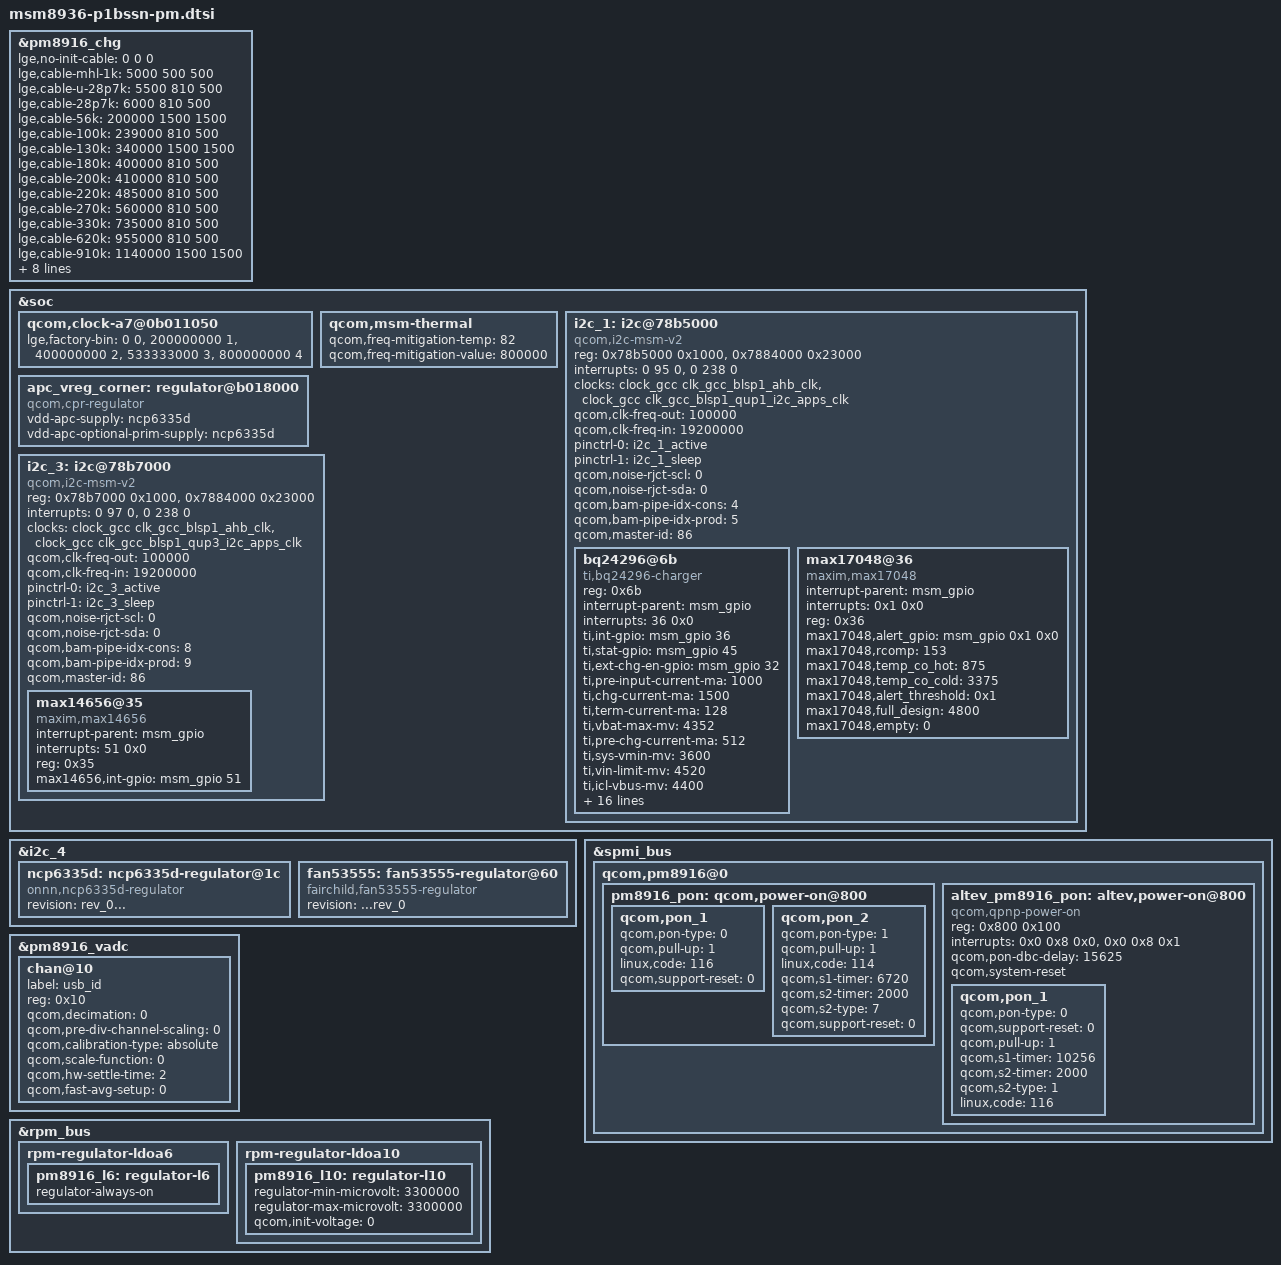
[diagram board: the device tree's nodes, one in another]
/* Copyright (c) 2012, Code Aurora Forum. All rights reserved.
 *
 * This program is free software; you can redistribute it and/or modify
* it under the terms of the GNU General Public License version 2 and
* only version 2 as published by the Free Software Foundation.
*
* This program is distributed in the hope that it will be useful,
* but WITHOUT ANY WARRANTY; without even the implied warranty of
* MERCHANTABILITY or FITNESS FOR A PARTICULAR PURPOSE.  See the
* GNU General Public License for more details.
*/

&pm8916_chg {
	status = "ok";

	lge,no-init-cable = <0 0 0>;
	lge,cable-mhl-1k = <5000 500 500>;
	lge,cable-u-28p7k = <5500 810 500>;
	lge,cable-28p7k = <6000 810 500>;
	lge,cable-56k = <200000 1500 1500>;
	lge,cable-100k = <239000 810 500>;
	lge,cable-130k = <340000 1500 1500>;
	lge,cable-180k = <400000 810 500>;
	lge,cable-200k = <410000 810 500>;
	lge,cable-220k = <485000 810 500>;
	lge,cable-270k = <560000 810 500>;
	lge,cable-330k = <735000 810 500>;
	lge,cable-620k = <955000 810 500>;
	lge,cable-910k = <1140000 1500 1500>;
	lge,cable-none = <1900000 810  500>;

	qcom,vddmax-mv = <4350>;
	qcom,vddsafe-mv = <4380>;
	qcom,vinmin-mv = <4470>;
	qcom,tchg-mins = <480>;
	qcom,btc-disabled = <1>;
	qcom,resume-soc = <98>;
	qcom,disable-vbatdet-based-recharge;
};

&soc{
	
	qcom,clock-a7@0b011050	{
		lge,factory-bin =
			<          0 0>,
			<  200000000 1>,
			<  400000000 2>,
			<  533333000 3>,
			<  800000000 4>;
	};

	qcom,msm-thermal {
		qcom,freq-mitigation-temp = <82>;
		qcom,freq-mitigation-value = <800000>;
	};

	i2c_1: i2c@78b5000 { /* BLSP1 QUP1 */
		compatible = "qcom,i2c-msm-v2";
		#address-cells = <1>;
		#size-cells = <0>;
		reg-names = "qup_phys_addr", "bam_phys_addr";
		reg = <0x78b5000 0x1000>,
		<0x7884000 0x23000>;
		interrupt-names = "qup_irq", "bam_irq";
		interrupts = <0 95 0>, <0 238 0>;
		clocks = <&clock_gcc clk_gcc_blsp1_ahb_clk>,
		<&clock_gcc clk_gcc_blsp1_qup1_i2c_apps_clk>;
		clock-names = "iface_clk", "core_clk";
		qcom,clk-freq-out = <100000>;
		qcom,clk-freq-in  = <19200000>;
		pinctrl-names = "i2c_active", "i2c_sleep";
		pinctrl-0 = <&i2c_1_active>;
		pinctrl-1 = <&i2c_1_sleep>;
		qcom,noise-rjct-scl = <0>;
		qcom,noise-rjct-sda = <0>;
		qcom,bam-pipe-idx-cons = <4>;
		qcom,bam-pipe-idx-prod = <5>;
		qcom,master-id = <86>;
	};
	apc_vreg_corner: regulator@b018000 {
           compatible = "qcom,cpr-regulator";
		vdd-apc-supply = <&ncp6335d >;
        vdd-apc-optional-prim-supply = <&ncp6335d>;
	};

	i2c_3: i2c@78b7000 { /* BLSP1 QUP3 */
		compatible = "qcom,i2c-msm-v2";
		#address-cells = <1>;
		#size-cells = <0>;
		reg-names = "qup_phys_addr", "bam_phys_addr";
		reg = <0x78b7000 0x1000>,
		<0x7884000 0x23000>;
		interrupt-names = "qup_irq", "bam_irq";
		interrupts = <0 97 0>, <0 238 0>;
		clocks = <&clock_gcc clk_gcc_blsp1_ahb_clk>,
		<&clock_gcc clk_gcc_blsp1_qup3_i2c_apps_clk>;
		clock-names = "iface_clk", "core_clk";
		qcom,clk-freq-out = <100000>;
		qcom,clk-freq-in  = <19200000>;
		pinctrl-names = "i2c_active", "i2c_sleep";
		pinctrl-0 = <&i2c_3_active>;
		pinctrl-1 = <&i2c_3_sleep>;
		qcom,noise-rjct-scl = <0>;
		qcom,noise-rjct-sda = <0>;
		qcom,bam-pipe-idx-cons = <8>;
		qcom,bam-pipe-idx-prod = <9>;
		qcom,master-id = <86>;
	};
};

&i2c_1 {
	bq24296@6b {
		status = "ok";
		compatible = "ti,bq24296-charger";
		reg = <0x6b>;
		interrupt-parent = <&msm_gpio>;
		interrupts = <36 0x0>;
		ti,int-gpio = <&msm_gpio 36 0>;
		ti,stat-gpio = <&msm_gpio 45 0>;
		ti,ext-chg-en-gpio = <&msm_gpio 32 0>;
		ti,pre-input-current-ma = <1000>;
		ti,chg-current-ma = <1500>;
		ti,term-current-ma = <128>;
		ti,vbat-max-mv = <4352>;
		ti,pre-chg-current-ma = <512>;
		ti,sys-vmin-mv = <3600>;
		ti,vin-limit-mv = <4520>;
		ti,icl-vbus-mv = <4400>;

		lge,no-init-cable = <0 0 0>;
		lge,cable-mhl-1k = <5000 500 500>;
		lge,cable-u-28p7k = <5500 2000 500>;
		lge,cable-28p7k = <6000 1200 500>;
		lge,cable-56k = <178000 1500 1500>;
		lge,cable-100k = <178500 2000 500>;
		lge,cable-130k = <340000 500 500>;
		lge,cable-180k = <400000 2000 500>;
		lge,cable-200k = <410000 2000 500>;
		lge,cable-220k = <485000 2000 500>;
		lge,cable-270k = <560000 2000 500>;
		lge,cable-330k = <735000 2000 500>;
		lge,cable-620k = <955000 2000 500>;
		lge,cable-910k = <1200000 1500 1500>;
		lge,cable-none = <1900000 2000	500>;

		qcom,bq24296-vadc = <&pm8916_vadc>;
	};
	max17048@36 {
                status = "ok";
                compatible = "maxim,max17048";
                interrupt-parent = <&msm_gpio>;
                interrupts = <0x1 0x0>;
                reg = <0x36>;
                max17048,alert_gpio = <&msm_gpio 0x1 0x0>;
                max17048,rcomp = <153>;
                max17048,temp_co_hot = <875>;
                max17048,temp_co_cold = <3375>;
                max17048,alert_threshold = <0x1>;
                max17048,full_design = <4800>;
                max17048,empty = <0>;
        };
};

&i2c_3 {
	max14656@35 {
		status = "ok";
		compatible = "maxim,max14656";
		interrupt-parent = <&msm_gpio>;
		interrupts = <51 0x0>;
		reg = <0x35>;
		max14656,int-gpio = <&msm_gpio 51 0>;
	};
};

&i2c_4 {
    ncp6335d: ncp6335d-regulator@1c {
	    compatible = "onnn,ncp6335d-regulator";
        revision = "rev_0...";
	};
    fan53555: fan53555-regulator@60 {
       compatible = "fairchild,fan53555-regulator";
       revision = "...rev_0";
	};
};

&spmi_bus {
	qcom,pm8916@0 {
		pm8916_pon: qcom,power-on@800 {
			qcom,pon_1 {
				qcom,pon-type = <0>;
				qcom,pull-up = <1>;
				linux,code = <116>;
				qcom,support-reset = <0>;
			};
			qcom,pon_2 {
				qcom,pon-type = <1>;
				qcom,pull-up = <1>;
				linux,code = <114>;
				qcom,s1-timer = <6720>;
				qcom,s2-timer = <2000>;
				qcom,s2-type = <7>;
				status = "ok";
				qcom,support-reset = <0>;
			};
		};
		altev_pm8916_pon: altev,power-on@800 {
			compatible = "qcom,qpnp-power-on";
			reg = <0x800 0x100>;
			interrupts = <0x0 0x8 0x0>,
				     <0x0 0x8 0x1>;
			interrupt-names = "kpdpwr", "resin";
			qcom,pon-dbc-delay = <15625>;
			qcom,system-reset;
			status = "okay";
			qcom,pon_1 {
				qcom,pon-type = <0>;
				qcom,support-reset = <0>;
				qcom,pull-up = <1>;
				qcom,s1-timer = <10256>;
				qcom,s2-timer = <2000>;
				qcom,s2-type = <1>;
				linux,code = <116>;
			};
		};
	};
};

&pm8916_vadc {
	chan@10 {
		label = "usb_id";
		reg = <0x10>;
		qcom,decimation = <0>;
		qcom,pre-div-channel-scaling = <0>;
		qcom,calibration-type = "absolute";
		qcom,scale-function = <0>;
		qcom,hw-settle-time = <2>;
		qcom,fast-avg-setup = <0>;
	};
};


&rpm_bus {
	rpm-regulator-ldoa6 {
		status = "okay";
		pm8916_l6: regulator-l6 {
			regulator-always-on;
			status = "okay";
		};
	};

	rpm-regulator-ldoa10 {
		status = "okay";
		pm8916_l10: regulator-l10 {
			regulator-min-microvolt = <3300000>;
			regulator-max-microvolt = <3300000>;
			qcom,init-voltage = <0>;
			status = "okay";
		};
	};
};

